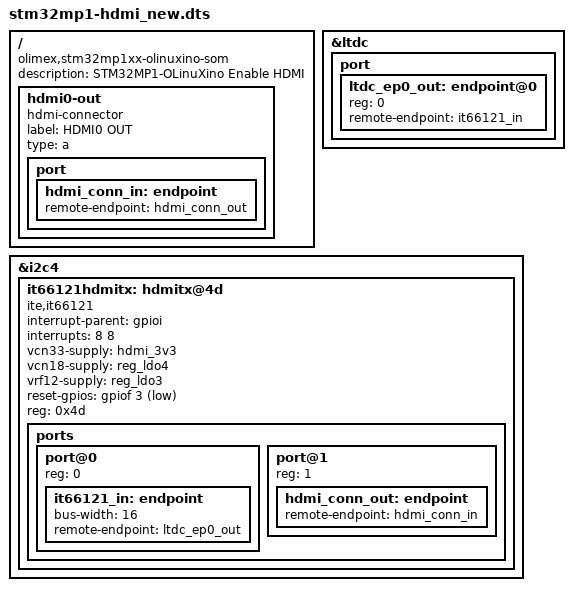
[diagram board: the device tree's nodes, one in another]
/dts-v1/;
/plugin/;

/ {
	compatible = "olimex,stm32mp1xx-olinuxino-som",
                     "olimex,stm32mp1xx-olinuxino-lime";

	description = "STM32MP1-OLinuXino Enable HDMI";

        fragment@0 {
                target-path = "/";
                __overlay__ {
		     hdmi0-out {
                            compatible = "hdmi-connector";
                            label = "HDMI0 OUT";
                            type = "a";

                            port {
                                hdmi_conn_in: endpoint {
                                   remote-endpoint = <&hdmi_conn_out>;
                                };
                           };
	          };
                };
        };


	fragment@1 {
		target = <&ltdc>;
		__overlay__ {
                           port {
 	                        #address-cells = <1>;
        	                #size-cells = <0>;

                                ltdc_ep0_out: endpoint@0 {
                                               reg = <0>;
                                               remote-endpoint = <&it66121_in>;
                                              };
                           };

	                 };
	};

	fragment@2 {
		target = <&i2c4>;
		__overlay__ {
			it66121hdmitx: hdmitx@4d {
                                          compatible = "ite,it66121";
                                          interrupt-parent = <&gpioi>;
                                          interrupts = <8 8>;         
                                          vcn33-supply = <&hdmi_3v3>;
                                          vcn18-supply = <&reg_ldo4>;
                                          vrf12-supply = <&reg_ldo3>;
                                          reset-gpios = <&gpiof 3 1>;
                                          reg = <0x4d>;
					  ports {
					       #address-cells = <1>;
//￼					       #size-cells = <1>;
						port@0 {
				                    reg = <0>;
				                    it66121_in: endpoint {
				                        bus-width = <16>;
				                        remote-endpoint = <&ltdc_ep0_out>;
                    				    };
                                               };

					
					
						port@1 {
                    				       reg = <1>;
					               hdmi_conn_out: endpoint {
                        			          remote-endpoint = <&hdmi_conn_in>;
                                                      };
                                                };

					};

                     };

		};
	};
};
	
